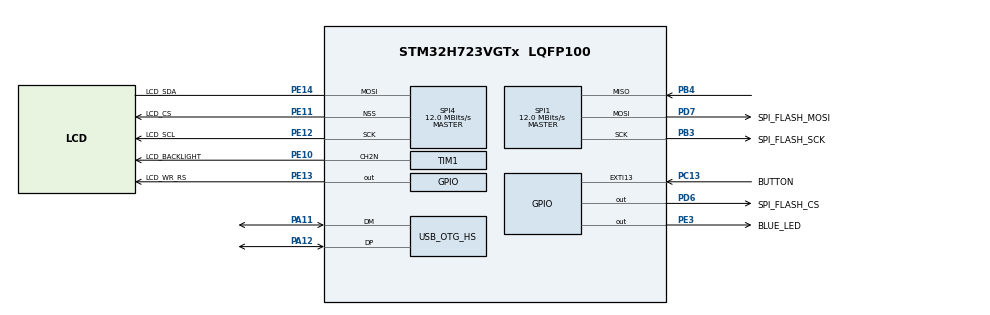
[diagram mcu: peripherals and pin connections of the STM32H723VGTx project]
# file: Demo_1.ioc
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ADC3.Channel-0\#ChannelRegularConversion=ADC_CHANNEL_TEMPSENSOR
ADC3.ClockPrescalerADC3=ADC_CLOCK_ASYNC_DIV256
ADC3.ContinuousConvMode=ENABLE
ADC3.NbrOfConversion=1
ADC3.NbrOfConversionFlag=1
ADC3.OffsetNumber-0\#ChannelRegularConversion=ADC_OFFSET_NONE
ADC3.OffsetSign-0\#ChannelRegularConversion=ADC3_OFFSET_SIGN_NEGATIVE
ADC3.Overrun=ADC_OVR_DATA_OVERWRITTEN
ADC3.OversamplingMode=ENABLE
ADC3.Rank-0\#ChannelRegularConversion=1
ADC3.Ratio=ADC3_OVERSAMPLING_RATIO_16
ADC3.RightBitShift=ADC_RIGHTBITSHIFT_4
ADC3.SamplingTime-0\#ChannelRegularConversion=ADC3_SAMPLETIME_640CYCLES_5
CORTEX_M7.default_mode_Activation=1
Dma.ADC3.0.Direction=DMA_PERIPH_TO_MEMORY
Dma.ADC3.0.EventEnable=DISABLE
Dma.ADC3.0.FIFOMode=DMA_FIFOMODE_DISABLE
Dma.ADC3.0.Instance=DMA1_Stream0
Dma.ADC3.0.MemDataAlignment=DMA_MDATAALIGN_HALFWORD
Dma.ADC3.0.MemInc=DMA_MINC_ENABLE
Dma.ADC3.0.Mode=DMA_CIRCULAR
Dma.ADC3.0.PeriphDataAlignment=DMA_PDATAALIGN_HALFWORD
Dma.ADC3.0.PeriphInc=DMA_PINC_DISABLE
Dma.ADC3.0.Polarity=HAL_DMAMUX_REQ_GEN_RISING
Dma.ADC3.0.Priority=DMA_PRIORITY_LOW
Dma.ADC3.0.RequestNumber=1
Dma.ADC3.0.SignalID=NONE
Dma.ADC3.0.SyncEnable=DISABLE
Dma.ADC3.0.SyncPolarity=HAL_DMAMUX_SYNC_NO_EVENT
Dma.ADC3.0.SyncRequestNumber=1
Dma.ADC3.0.SyncSignalID=NONE
Dma.Request0=ADC3
Mcu.Family=STM32H7
Mcu.Name=STM32H723VGTx
Mcu.Package=LQFP100
Mcu.UserConstants=TFT96,1
NVIC.ADC3_IRQn=true\:0\:0\:false\:false\:true\:true\:true\:true
NVIC.DMA1_Stream0_IRQn=true\:0\:0\:false\:false\:true\:false\:true\:true
NVIC.EXTI15_10_IRQn=true\:0\:0\:false\:false\:true\:true\:true\:true
NVIC.OTG_HS_IRQn=true\:0\:0\:false\:false\:true\:false\:true\:true
NVIC.PriorityGroup=NVIC_PRIORITYGROUP_4
PA11.Mode=Device_Only_FS
PA11.Signal=USB_OTG_HS_DM
PA12.Mode=Device_Only_FS
PA12.Signal=USB_OTG_HS_DP
PA13(JTMS/SWDIO).Mode=Serial_Wire
PA13(JTMS/SWDIO).Signal=DEBUG_JTMS-SWDIO
PA14(JTCK/SWCLK).Mode=Serial_Wire
PA14(JTCK/SWCLK).Signal=DEBUG_JTCK-SWCLK
PB3(JTDO/TRACESWO).GPIO_Label=SPI_FLASH_SCK
PB3(JTDO/TRACESWO).Mode=Full_Duplex_Master
PB3(JTDO/TRACESWO).Signal=SPI1_SCK
PB4(NJTRST).Mode=Full_Duplex_Master
PB4(NJTRST).Signal=SPI1_MISO
PC13.GPIO_Label=BUTTON
PC13.GPIO_PuPd=GPIO_PULLDOWN
PC13.Signal=GPXTI13
PC14-OSC32_IN.Mode=LSE-External-Oscillator
PC14-OSC32_IN.Signal=RCC_OSC32_IN
PC15-OSC32_OUT.Mode=LSE-External-Oscillator
PC15-OSC32_OUT.Signal=RCC_OSC32_OUT
PD6.GPIO_Label=SPI_FLASH_CS
PD6.Signal=GPIO_Output
PD7.GPIO_Label=SPI_FLASH_MOSI
PD7.Mode=Full_Duplex_Master
PD7.Signal=SPI1_MOSI
PE10.GPIO_Label=LCD_BACKLIGHT
PE10.Mode=PWM Generation2 CH2N
PE10.Signal=TIM1_CH2N
PE11.GPIO_Label=LCD_CS
PE11.Mode=NSS_Signal_Hard_Output
PE11.Signal=SPI4_NSS
PE12.GPIO_Label=LCD_SCL
PE12.Mode=Simplex_Bidirectional_Master
PE12.Signal=SPI4_SCK
PE13.GPIO_Label=LCD_WR_RS
PE13.Signal=GPIO_Output
PE14.GPIO_Label=LCD_SDA
PE14.Mode=Simplex_Bidirectional_Master
PE14.Signal=SPI4_MOSI
PE3.GPIO_Label=BLUE_LED
PE3.Signal=GPIO_Output
PH0-OSC_IN.Mode=HSE-External-Oscillator
PH0-OSC_IN.Signal=RCC_OSC_IN
PH1-OSC_OUT.Mode=HSE-External-Oscillator
PH1-OSC_OUT.Signal=RCC_OSC_OUT
ProjectManager.HeapSize=0x1000
ProjectManager.StackSize=0x1000
ProjectManager.TargetToolchain=STM32CubeIDE
RCC.ADCCLockSelection=RCC_ADCCLKSOURCE_CLKP
RCC.ADCFreq_Value=64000000
RCC.APB1Freq_Value=137500000
RCC.APB2Freq_Value=137500000
RCC.APB3Freq_Value=137500000
RCC.APB4Freq_Value=137500000
RCC.CortexFreq_Value=550000000
RCC.D1PPRE=RCC_APB3_DIV2
RCC.D2PPRE1=RCC_APB1_DIV2
RCC.D2PPRE2=RCC_APB2_DIV2
RCC.D3PPRE=RCC_APB4_DIV2
RCC.DIVM1=2
RCC.DIVM2=5
RCC.DIVM3=25
RCC.DIVN1=44
RCC.DIVN2=40
RCC.DIVN3=192
RCC.DIVP1=1
RCC.DIVP2=1
RCC.DIVQ3=4
RCC.HCLKFreq_Value=275000000
RCC.HPRE=RCC_HCLK_DIV2
RCC.PLL2FRACN=0
RCC.PLL3FRACN=0
RCC.PLLFRACN=0
RCC.PLLSourceVirtual=RCC_PLLSOURCE_HSE
RCC.PWR_Regulator_Voltage_Scale=PWR_REGULATOR_VOLTAGE_SCALE0
RCC.SPI123CLockSelection=RCC_SPI123CLKSOURCE_PLL3
RCC.SYSCLKFreq_VALUE=550000000
RCC.SYSCLKSource=RCC_SYSCLKSOURCE_PLLCLK
RCC.Spi45ClockSelection=RCC_SPI45CLKSOURCE_PLL3
RCC.USBCLockSelection=RCC_USBCLKSOURCE_PLL3
RCC.USBFreq_Value=48000000
SPI1.BaudRatePrescaler=SPI_BAUDRATEPRESCALER_8
SPI1.CalculateBaudRate=12.0 MBits/s
SPI1.DataSize=SPI_DATASIZE_8BIT
SPI1.Direction=SPI_DIRECTION_2LINES
SPI1.Mode=SPI_MODE_MASTER
SPI1.VirtualType=VM_MASTER
SPI4.BaudRatePrescaler=SPI_BAUDRATEPRESCALER_4
SPI4.CalculateBaudRate=12.0 MBits/s
SPI4.DataSize=SPI_DATASIZE_8BIT
SPI4.Direction=SPI_DIRECTION_1LINE
SPI4.Mode=SPI_MODE_MASTER
SPI4.VirtualNSS=VM_NSSHARD
SPI4.VirtualType=VM_MASTER
TIM1.Channel-PWM\ Generation2\ CH2N=TIM_CHANNEL_2
TIM1.Period=100-1
TIM1.Prescaler=275-1
TIM1.Pulse-PWM\ Generation2\ CH2N=50
USB_DEVICE.CLASS_NAME_HS=CDC
USB_DEVICE.VirtualMode=Cdc
USB_DEVICE.VirtualModeHS=Cdc_HS
USB_OTG_HS.VirtualMode-Device_Only_FS=Device_Only_FS
VP_ADC3_TempSens_Input.Mode=IN-TempSens
VP_CRC_VS_CRC.Mode=CRC_Activate
VP_MEMORYMAP_VS_MEMORYMAP.Mode=CurAppReg
VP_RNG_VS_RNG.Mode=RNG_Activate
VP_TIM1_VS_ClockSourceINT.Mode=Internal
VP_USB_DEVICE_VS_USB_DEVICE_CDC_HS.Mode=CDC_HS
board=custom

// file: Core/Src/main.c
/* USER CODE BEGIN Header */
/**
  ******************************************************************************
  * @file           : main.c
  * @brief          : Main program body
  ******************************************************************************
  * @attention
  *
  * Copyright (c) 2024 STMicroelectronics.
  * All rights reserved.
  *
  * This software is licensed under terms that can be found in the LICENSE file
  * in the root directory of this software component.
  * If no LICENSE file comes with this software, it is provided AS-IS.
  *
  ******************************************************************************
  */
/* USER CODE END Header */
#include "main.h"
#include "adc.h"
#include "crc.h"
#include "dma.h"
#include "memorymap.h"
#include "rng.h"
#include "spi.h"
#include "tim.h"
#include "usb_device.h"
#include "gpio.h"

/* USER CODE BEGIN Includes */
#include "lcd.h"
/* USER CODE END Includes */

/* USER CODE BEGIN PD */

#define LCD_BACKLIGHT_TIMER htim1
#define LCD_BACKLIGHT_CHAN  TIM_CHANNEL_2
/* USER CODE END PD */

void SystemClock_Config(void);
void PeriphCommonClock_Config(void);
static void MPU_Config(void);

int main(void)
{

  /* MPU Configuration--------------------------------------------------------*/
  MPU_Config();

  /* MCU Configuration--------------------------------------------------------*/

  /* Reset of all peripherals, Initializes the Flash interface and the Systick. */
  HAL_Init();

  /* Configure the system clock */
  SystemClock_Config();

  /* Configure the peripherals common clocks */
  PeriphCommonClock_Config();

  /* Initialize all configured peripherals */
  MX_GPIO_Init();
  MX_DMA_Init();
  MX_CRC_Init();
  MX_USB_DEVICE_Init();
  MX_TIM1_Init();
  MX_SPI1_Init();
  MX_RNG_Init();
  MX_ADC3_Init();
  MX_SPI4_Init();
  /* USER CODE BEGIN 2 */

  HAL_TIMEx_PWMN_Start(&LCD_BACKLIGHT_TIMER, LCD_BACKLIGHT_CHAN);

  LCD_Test();

  char text_buf[100];
  uint8_t counter = 0;

  LCD_SetBrightness(80);

  /* USER CODE END 2 */

  /* Infinite loop */
  while (1)
  {

    /* USER CODE BEGIN 3 */

	HAL_GPIO_TogglePin(BLUE_LED_GPIO_Port, BLUE_LED_Pin);
	HAL_Delay(1000);

	counter++;
	snprintf(text_buf, sizeof(text_buf), "Hello world! (%u)", counter);
	LCD_ShowString(4, 58, 160, 16, 16, (uint8_t*)text_buf);
  }
  /* USER CODE END 3 */
}

void SystemClock_Config(void)
{
  RCC_OscInitTypeDef RCC_OscInitStruct = {0};
  RCC_ClkInitTypeDef RCC_ClkInitStruct = {0};

  /** Supply configuration update enable
  */
  HAL_PWREx_ConfigSupply(PWR_LDO_SUPPLY);

  /** Configure the main internal regulator output voltage
  */
  __HAL_PWR_VOLTAGESCALING_CONFIG(PWR_REGULATOR_VOLTAGE_SCALE0);

  while(!__HAL_PWR_GET_FLAG(PWR_FLAG_VOSRDY)) {}

  /** Initializes the RCC Oscillators according to the specified parameters
  * in the RCC_OscInitTypeDef structure.
  */
  RCC_OscInitStruct.OscillatorType = RCC_OSCILLATORTYPE_HSI48|RCC_OSCILLATORTYPE_HSI
                              |RCC_OSCILLATORTYPE_HSE;
  RCC_OscInitStruct.HSEState = RCC_HSE_ON;
  RCC_OscInitStruct.HSIState = RCC_HSI_DIV1;
  RCC_OscInitStruct.HSICalibrationValue = 64;
  RCC_OscInitStruct.HSI48State = RCC_HSI48_ON;
  RCC_OscInitStruct.PLL.PLLState = RCC_PLL_ON;
  RCC_OscInitStruct.PLL.PLLSource = RCC_PLLSOURCE_HSE;
  RCC_OscInitStruct.PLL.PLLM = 2;
  RCC_OscInitStruct.PLL.PLLN = 44;
  RCC_OscInitStruct.PLL.PLLP = 1;
  RCC_OscInitStruct.PLL.PLLQ = 2;
  RCC_OscInitStruct.PLL.PLLR = 2;
  RCC_OscInitStruct.PLL.PLLRGE = RCC_PLL1VCIRANGE_3;
  RCC_OscInitStruct.PLL.PLLVCOSEL = RCC_PLL1VCOWIDE;
  RCC_OscInitStruct.PLL.PLLFRACN = 0;
  if (HAL_RCC_OscConfig(&RCC_OscInitStruct) != HAL_OK)
  {
    Error_Handler();
  }

  /** Initializes the CPU, AHB and APB buses clocks
  */
  RCC_ClkInitStruct.ClockType = RCC_CLOCKTYPE_HCLK|RCC_CLOCKTYPE_SYSCLK
                              |RCC_CLOCKTYPE_PCLK1|RCC_CLOCKTYPE_PCLK2
                              |RCC_CLOCKTYPE_D3PCLK1|RCC_CLOCKTYPE_D1PCLK1;
  RCC_ClkInitStruct.SYSCLKSource = RCC_SYSCLKSOURCE_PLLCLK;
  RCC_ClkInitStruct.SYSCLKDivider = RCC_SYSCLK_DIV1;
  RCC_ClkInitStruct.AHBCLKDivider = RCC_HCLK_DIV2;
  RCC_ClkInitStruct.APB3CLKDivider = RCC_APB3_DIV2;
  RCC_ClkInitStruct.APB1CLKDivider = RCC_APB1_DIV2;
  RCC_ClkInitStruct.APB2CLKDivider = RCC_APB2_DIV2;
  RCC_ClkInitStruct.APB4CLKDivider = RCC_APB4_DIV2;

  if (HAL_RCC_ClockConfig(&RCC_ClkInitStruct, FLASH_LATENCY_3) != HAL_OK)
  {
    Error_Handler();
  }
}

void PeriphCommonClock_Config(void)
{
  RCC_PeriphCLKInitTypeDef PeriphClkInitStruct = {0};

  /** Initializes the peripherals clock
  */
  PeriphClkInitStruct.PeriphClockSelection = RCC_PERIPHCLK_USB|RCC_PERIPHCLK_SPI1
                              |RCC_PERIPHCLK_SPI4|RCC_PERIPHCLK_CKPER;
  PeriphClkInitStruct.PLL3.PLL3M = 25;
  PeriphClkInitStruct.PLL3.PLL3N = 192;
  PeriphClkInitStruct.PLL3.PLL3P = 2;
  PeriphClkInitStruct.PLL3.PLL3Q = 4;
  PeriphClkInitStruct.PLL3.PLL3R = 2;
  PeriphClkInitStruct.PLL3.PLL3RGE = RCC_PLL3VCIRANGE_0;
  PeriphClkInitStruct.PLL3.PLL3VCOSEL = RCC_PLL3VCOMEDIUM;
  PeriphClkInitStruct.PLL3.PLL3FRACN = 0;
  PeriphClkInitStruct.CkperClockSelection = RCC_CLKPSOURCE_HSI;
  PeriphClkInitStruct.Spi123ClockSelection = RCC_SPI123CLKSOURCE_PLL3;
  PeriphClkInitStruct.Spi45ClockSelection = RCC_SPI45CLKSOURCE_PLL3;
  PeriphClkInitStruct.UsbClockSelection = RCC_USBCLKSOURCE_PLL3;
  if (HAL_RCCEx_PeriphCLKConfig(&PeriphClkInitStruct) != HAL_OK)
  {
    Error_Handler();
  }
}

 /* MPU Configuration */

void MPU_Config(void)
{
  MPU_Region_InitTypeDef MPU_InitStruct = {0};

  /* Disables the MPU */
  HAL_MPU_Disable();

  /** Initializes and configures the Region and the memory to be protected
  */
  MPU_InitStruct.Enable = MPU_REGION_ENABLE;
  MPU_InitStruct.Number = MPU_REGION_NUMBER0;
  MPU_InitStruct.BaseAddress = 0x0;
  MPU_InitStruct.Size = MPU_REGION_SIZE_4GB;
  MPU_InitStruct.SubRegionDisable = 0x87;
  MPU_InitStruct.TypeExtField = MPU_TEX_LEVEL0;
  MPU_InitStruct.AccessPermission = MPU_REGION_NO_ACCESS;
  MPU_InitStruct.DisableExec = MPU_INSTRUCTION_ACCESS_DISABLE;
  MPU_InitStruct.IsShareable = MPU_ACCESS_SHAREABLE;
  MPU_InitStruct.IsCacheable = MPU_ACCESS_NOT_CACHEABLE;
  MPU_InitStruct.IsBufferable = MPU_ACCESS_NOT_BUFFERABLE;

  HAL_MPU_ConfigRegion(&MPU_InitStruct);
  /* Enables the MPU */
  HAL_MPU_Enable(MPU_PRIVILEGED_DEFAULT);

}

void Error_Handler(void)
{
  __disable_irq();
  while (1)
  {
  }
}
